# PRM_DEVICE register map
Vendor: Texas Instruments
Peripheral module from a debugger description file (folder am335x).
Registers are 32-bit, access per field, no defined reset value unless marked. A register's access mark holds for its fields unless they carry their own. Offsets are as the file gives them; lines under a group give offsets from that group; [hi:lo] are bit positions; {n}, {i} and the like mark numbered series; 'fields as' and 'values as' point back to an identical list; <NAME> marks a mode.

## PRM_DEVICE
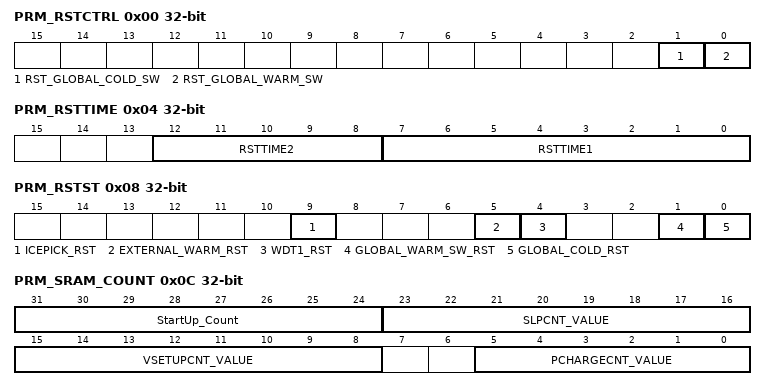
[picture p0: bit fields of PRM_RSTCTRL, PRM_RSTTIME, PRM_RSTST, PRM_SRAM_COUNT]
0x00 PRM_RSTCTRL — Global software cold and warm reset control. This register is auto-cleared. Only write 1 is possible. A read returns 0 only.
  [1] RST_GLOBAL_COLD_SW rw — Global COLD software reset control. This bit is reset only upon a global cold source of reset. Read returns 0.
    0=Global COLD software reset is cleared; 1=Asserts a global COLD software reset. The software must ensure the SDRAM is properly put in sef-refresh mode before applying this reset.
  [0] RST_GLOBAL_WARM_SW rw — Global WARM software reset control. This bit is reset upon any global source of reset (warm and cold). Read returns 0.
    0=Global warm software reset is cleared; 1=Asserts a global warm software reset
0x04 PRM_RSTTIME — Reset duration control. [warm reset insensitive]
  [12:8] RSTTIME2 rw — (Power domain) reset duration 2 (number of CLK_M_OSC clock cycles)
  [7:0] RSTTIME1 rw — (Global) reset duration 1 (number of CLK_M_OSC clock cycles)
0x08 PRM_RSTST — This register logs the global reset sources. Each bit is set upon release of the domain reset signal. Must be cleared by software. [warm reset insensitive]
  [9] ICEPICK_RST rw — IcePick reset event. This is a source of global warm reset initiated by the emulation. [warm reset insensitive]
    0=No ICEPICK reset; 1=IcePick reset has occurred
  [5] EXTERNAL_WARM_RST rw — External warm reset event [warm reset insensitive]
    0=No global warm reset; 1=Global external warm reset has occurred
  [4] WDT1_RST rw — Watchdog1 timer reset event. This is a source of global WARM reset. [warm reset insensitive]
    0=No watchdog reset; 1=watchdog reset has occurred
  [1] GLOBAL_WARM_SW_RST rw — Global warm software reset event [warm reset insensitive]
    0=No global warm SW reset; 1=Global warm SW reset has occurred
  [0] GLOBAL_COLD_RST rw — Power-on (cold) reset event [warm reset insensitive]
    0=No power-on reset; 1=Power-on reset has occurred
0x0C PRM_SRAM_COUNT — Common setup for SRAM LDO transition counters. Applies to all voltage domains. [warm reset insensitive]
  [31:24] StartUp_Count rw — Determines the start-up duration of SRAM and ABB LDO. The duration is computed as 16 x NbCycles of system clock cycles. Target is 50us.
  [23:16] SLPCNT_VALUE rw — Delay between retention/off assertion of last SRAM bank and SRAMALLRET signal to LDO is driven high. Counting on system clock. Target is 2us.
  [15:8] VSETUPCNT_VALUE rw — SRAM LDO rampup time from retention to active mode. The duration is computed as 8 x NbCycles of system clock cycles. Target is 30us.
  [5:0] PCHARGECNT_VALUE rw — Delay between de-assertion of standby_rta_ret_on and standby_rta_ret_good. Counting on system clock. Target is 600ns.
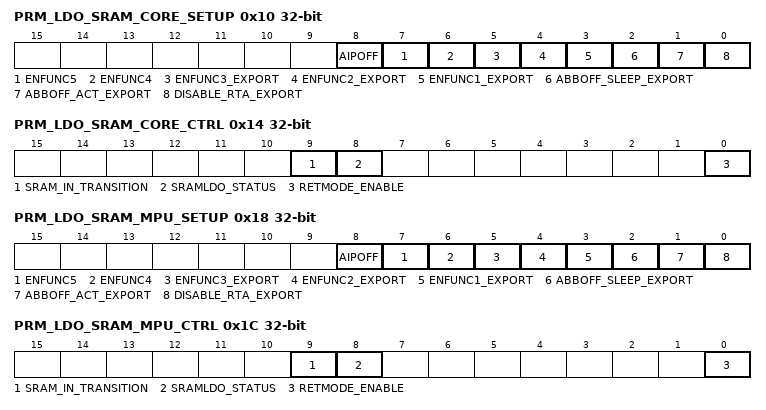
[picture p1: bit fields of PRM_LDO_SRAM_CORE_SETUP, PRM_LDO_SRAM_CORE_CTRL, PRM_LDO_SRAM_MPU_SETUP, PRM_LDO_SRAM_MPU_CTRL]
0x10 PRM_LDO_SRAM_CORE_SETUP — Setup of the SRAM LDO for CORE voltage domain. [warm reset insensitive]
  [8] AIPOFF rw — Override on AIPOFF input of SRAM LDO.
    0=No_Override (AIPOFF signal is not overriden); 1=Override (AIPOFF signal is overriden to '1'. Corresponding SRAM LDO is disabled and in HZ mode.)
  [7] ENFUNC5 rw — ENFUNC5 input of SRAM LDO.
    0=One_step (Active to retention is a one step transfer); 1=Two_step (Active to retention is a two steps transfer)
  [6] ENFUNC4 rw — ENFUNC4 input of SRAM LDO.
    0=Ext_clock (One external clock is supplied); 1=No_ext_clock (No external clock is supplied)
  [5] ENFUNC3_EXPORT rw — ENFUNC3 input of SRAM LDO. After PowerOn reset and Efuse sensing, this bitfield is automatically loaded with an Efuse value from control module. Bitfield remains writable after this.
    0=Sub_regul_disabled (Sub regulation is disabled); 1=Sub_regul_enabled (Sub regulation is enabled)
  [4] ENFUNC2_EXPORT rw — ENFUNC2 input of SRAM LDO. After PowerOn reset and Efuse sensing, this bitfield is automatically loaded with an Efuse value from control module. Bitfield remains writable after this.
    0=Ext_cap (External cap is used); 1=No_ext_cap (External cap is not used)
  [3] ENFUNC1_EXPORT rw — ENFUNC1 input of SRAM LDO. After PowerOn reset and Efuse sensing, this bitfield is automatically loaded with an Efuse value from control module. Bitfield remains writable after this.
    0=Short_prot_disabled (Short circuit protection is disabled); 1=Short_prot_enabled (Short circuit protection is enabled)
  [2] ABBOFF_SLEEP_EXPORT rw — Determines whether SRAMNWA is supplied by VDDS or VDDAR during deep-sleep. After PowerOn reset and Efuse sensing, this bitfield is automatically loaded with an Efuse value from control module. Bitfield remains writable after this.
    0=SRAMNW_SLP_VDDS (SRAMNWA supplied with VDDS); 1=SRAMNW_SLP_VDDAR (SRAMNWA supplied with VDDAR)
  [1] ABBOFF_ACT_EXPORT rw — Determines whether SRAMNWA is supplied by VDDS or VDDAR during active mode. After PowerOn reset and Efuse sensing, this bitfield is automatically loaded with an Efuse value from control module. Bitfield remains writable after this.
    0=SRAMNW_ACT_VDDS (SRAMNWA supplied with VDDS); 1=SRAMNW_ACT_VDDAR (SRAMNWA supplied with VDDAR)
  [0] DISABLE_RTA_EXPORT rw — Control for HD memory RTA feature. After PowerOn reset and Efuse sensing, this bitfield is automatically loaded with an Efuse value from control module. Bitfield remains writable after this.
    0=RTA_ENABLED (HD memory RTA feature is enabled); 1=RTA_DISABLED (HD memory RTA feature is disabled)
0x14 PRM_LDO_SRAM_CORE_CTRL — Control and status of the SRAM LDO for CORE voltage domain. [warm reset insensitive]
  [9] SRAM_IN_TRANSITION ro — Status indicating SRAM LDO state machine state.
    0=IDLE (SRAM LDO state machine is stable); 1=IN_TRANSITION (SRAM LDO state machine is in transition state)
  [8] SRAMLDO_STATUS ro
    0=ACTIVE (SRAMLDO is in ACTIVE mode.); 1=RETENTION (SRAMLDO is on RETENTION mode.)
  [0] RETMODE_ENABLE rw — Control if the SRAM LDO retention mode is used or not.
    0=Disabled (SRAM LDO is not allowed to go to RET mode); 1=Enabled (SRAM LDO go to RET mode when all memory of voltage domain are OFF or RET)
0x18 PRM_LDO_SRAM_MPU_SETUP — Setup of the SRAM LDO for MPU voltage domain. [warm reset insensitive]
  fields as PRM_LDO_SRAM_CORE_SETUP
0x1C PRM_LDO_SRAM_MPU_CTRL — Control and status of the SRAM LDO for MPU voltage domain. [warm reset insensitive]
  fields as PRM_LDO_SRAM_CORE_CTRL
